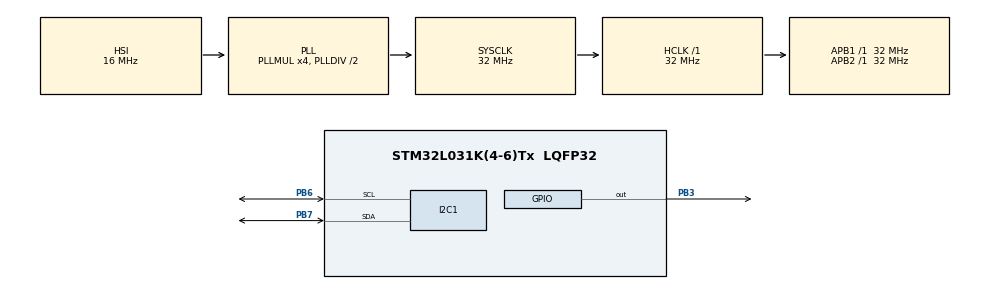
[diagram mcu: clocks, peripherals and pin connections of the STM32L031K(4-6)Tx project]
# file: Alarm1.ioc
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I2C1.Timing=0x00B07CB4
Mcu.Family=STM32L0
Mcu.Name=STM32L031K(4-6)Tx
Mcu.Package=LQFP32
NVIC.RTC_IRQn=true\:0\:0\:false\:false\:true\:true\:true\:true
PA13.Mode=Serial_Wire
PA13.Signal=SYS_SWDIO
PA14.Mode=Serial_Wire
PA14.Signal=SYS_SWCLK
PB3.Signal=GPIO_Output
PB6.GPIO_Pu=GPIO_NOPULL
PB6.Mode=I2C
PB6.Signal=I2C1_SCL
PB7.GPIO_Pu=GPIO_NOPULL
PB7.Mode=I2C
PB7.Signal=I2C1_SDA
PC14-OSC32_IN.Mode=LSE-External-Oscillator
PC14-OSC32_IN.Signal=RCC_OSC32_IN
PC15-OSC32_OUT.Mode=LSE-External-Oscillator
PC15-OSC32_OUT.Signal=RCC_OSC32_OUT
ProjectManager.HeapSize=0x200
ProjectManager.StackSize=0x400
ProjectManager.TargetToolchain=STM32CubeIDE
RCC.AHBFreq_Value=32000000
RCC.APB1Freq_Value=32000000
RCC.APB1TimFreq_Value=32000000
RCC.APB2Freq_Value=32000000
RCC.APB2TimFreq_Value=32000000
RCC.HCLKFreq_Value=32000000
RCC.HSE_VALUE=8000000
RCC.HSI16_VALUE=16000000
RCC.HSI48_VALUE=48000000
RCC.HSI_VALUE=16000000
RCC.MSI_VALUE=2097000
RCC.PLLMUL=RCC_PLLMUL_4
RCC.RTCClockSelection=RCC_RTCCLKSOURCE_LSE
RCC.RTCClockSelectionVirtual=RCC_RTCCLKSOURCE_LSE
RCC.SYSCLKFreq_VALUE=32000000
RCC.SYSCLKSource=RCC_SYSCLKSOURCE_PLLCLK
RCC.VCOOutputFreq_Value=64000000
RTC.Alarm-Alarm\ A=RTC_ALARM_A
RTC.Date=7
RTC.Format=RTC_FORMAT_BIN
RTC.Hours=12
RTC.Hours_A-Alarm\ A=12
RTC.Minutes=23
RTC.Minutes_A-Alarm\ A=32
RTC.Month=RTC_MONTH_JULY
RTC.Seconds_A-Alarm\ A=10
RTC.WeekDay=RTC_WEEKDAY_SUNDAY
VP_RTC_VS_RTC_Activate.Mode=RTC_Enabled
VP_RTC_VS_RTC_Alarm_A_Intern.Mode=Alarm A
VP_RTC_VS_RTC_Calendar.Mode=RTC_Calendar
board=NUCLEO-L031K6

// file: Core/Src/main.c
/* USER CODE BEGIN Header */
/**
  ******************************************************************************
  * @file           : main.c
  * @brief          : Main program body
  ******************************************************************************
  * @attention
  *
  * Copyright (c) 2026 STMicroelectronics.
  * All rights reserved.
  *
  * This software is licensed under terms that can be found in the LICENSE file
  * in the root directory of this software component.
  * If no LICENSE file comes with this software, it is provided AS-IS.
  *
  ******************************************************************************
  */
/* USER CODE END Header */
#include "main.h"
#include "PCA9548.h"

/* USER CODE BEGIN PM */

#define				BME280_ADDRESS				0xEC
#define				BME280_DEVICE_ID			0xD0
/* USER CODE END PM */

I2C_HandleTypeDef hi2c1;

RTC_HandleTypeDef hrtc;

/* USER CODE BEGIN PV */
uint8_t status,data,channel;
/* USER CODE END PV */

void SystemClock_Config(void);
static void MX_GPIO_Init(void);
static void MX_RTC_Init(void);
static void MX_I2C1_Init(void);

/* USER CODE BEGIN 0 */

/* Function to check whether the device is ready or not at corresponding address */
/*for (uint8_t addr = 0;  addr < 128; addr++)
{
	  if(HAL_I2C_IsDeviceReady(&hi2c1, addr << 1, 2, 100) == HAL_OK)
	  {
		  status = addr;
	  }
}*/

/* RTC Callback */
void HAL_RTC_AlarmAEventCallback(RTC_HandleTypeDef *hrtc)
{
	//
	HAL_GPIO_TogglePin(GPIOB, GPIO_PIN_3);
}

/* USER CODE END 0 */

int main(void)
{

  /* MCU Configuration--------------------------------------------------------*/

  /* Reset of all peripherals, Initializes the Flash interface and the Systick. */
  HAL_Init();

  /* Configure the system clock */
  SystemClock_Config();

  /* Initialize all configured peripherals */
  MX_GPIO_Init();
  MX_RTC_Init();
  MX_I2C1_Init();
  /* USER CODE BEGIN 2 */
  PCA9548_SelectChannel(PCA9548A_ADDR,PCA9548_CHANNEL0_ENABLED);

  status = HAL_I2C_Mem_Read(&hi2c1, BME280_ADDRESS, BME280_DEVICE_ID, 1, &data, 1, 100);

  //status = HAL_I2C_Master_Transmit(&hi2c1, PCA9548A_ADDR, &data, 1, HAL_MAX_DELAY);
  /* USER CODE END 2 */

  /* Infinite loop */
  while (1)
  {

  }
}

void SystemClock_Config(void)
{
  RCC_OscInitTypeDef RCC_OscInitStruct = {0};
  RCC_ClkInitTypeDef RCC_ClkInitStruct = {0};
  RCC_PeriphCLKInitTypeDef PeriphClkInit = {0};

  /** Configure the main internal regulator output voltage
  */
  __HAL_PWR_VOLTAGESCALING_CONFIG(PWR_REGULATOR_VOLTAGE_SCALE1);

  /** Configure LSE Drive Capability
  */
  HAL_PWR_EnableBkUpAccess();
  __HAL_RCC_LSEDRIVE_CONFIG(RCC_LSEDRIVE_LOW);

  /** Initializes the RCC Oscillators according to the specified parameters
  * in the RCC_OscInitTypeDef structure.
  */
  RCC_OscInitStruct.OscillatorType = RCC_OSCILLATORTYPE_HSI|RCC_OSCILLATORTYPE_LSE;
  RCC_OscInitStruct.LSEState = RCC_LSE_ON;
  RCC_OscInitStruct.HSIState = RCC_HSI_ON;
  RCC_OscInitStruct.HSICalibrationValue = RCC_HSICALIBRATION_DEFAULT;
  RCC_OscInitStruct.PLL.PLLState = RCC_PLL_ON;
  RCC_OscInitStruct.PLL.PLLSource = RCC_PLLSOURCE_HSI;
  RCC_OscInitStruct.PLL.PLLMUL = RCC_PLLMUL_4;
  RCC_OscInitStruct.PLL.PLLDIV = RCC_PLLDIV_2;
  if (HAL_RCC_OscConfig(&RCC_OscInitStruct) != HAL_OK)
  {
    Error_Handler();
  }

  /** Initializes the CPU, AHB and APB buses clocks
  */
  RCC_ClkInitStruct.ClockType = RCC_CLOCKTYPE_HCLK|RCC_CLOCKTYPE_SYSCLK
                              |RCC_CLOCKTYPE_PCLK1|RCC_CLOCKTYPE_PCLK2;
  RCC_ClkInitStruct.SYSCLKSource = RCC_SYSCLKSOURCE_PLLCLK;
  RCC_ClkInitStruct.AHBCLKDivider = RCC_SYSCLK_DIV1;
  RCC_ClkInitStruct.APB1CLKDivider = RCC_HCLK_DIV1;
  RCC_ClkInitStruct.APB2CLKDivider = RCC_HCLK_DIV1;

  if (HAL_RCC_ClockConfig(&RCC_ClkInitStruct, FLASH_LATENCY_1) != HAL_OK)
  {
    Error_Handler();
  }
  PeriphClkInit.PeriphClockSelection = RCC_PERIPHCLK_I2C1|RCC_PERIPHCLK_RTC;
  PeriphClkInit.I2c1ClockSelection = RCC_I2C1CLKSOURCE_PCLK1;
  PeriphClkInit.RTCClockSelection = RCC_RTCCLKSOURCE_LSE;
  if (HAL_RCCEx_PeriphCLKConfig(&PeriphClkInit) != HAL_OK)
  {
    Error_Handler();
  }
}

static void MX_I2C1_Init(void)
{

  hi2c1.Instance = I2C1;
  hi2c1.Init.Timing = 0x00B07CB4;
  hi2c1.Init.OwnAddress1 = 0;
  hi2c1.Init.AddressingMode = I2C_ADDRESSINGMODE_7BIT;
  hi2c1.Init.DualAddressMode = I2C_DUALADDRESS_DISABLE;
  hi2c1.Init.OwnAddress2 = 0;
  hi2c1.Init.OwnAddress2Masks = I2C_OA2_NOMASK;
  hi2c1.Init.GeneralCallMode = I2C_GENERALCALL_DISABLE;
  hi2c1.Init.NoStretchMode = I2C_NOSTRETCH_DISABLE;
  if (HAL_I2C_Init(&hi2c1) != HAL_OK)
  {
    Error_Handler();
  }

  /** Configure Analogue filter
  */
  if (HAL_I2CEx_ConfigAnalogFilter(&hi2c1, I2C_ANALOGFILTER_ENABLE) != HAL_OK)
  {
    Error_Handler();
  }

  /** Configure Digital filter
  */
  if (HAL_I2CEx_ConfigDigitalFilter(&hi2c1, 0) != HAL_OK)
  {
    Error_Handler();
  }

}

static void MX_RTC_Init(void)
{

  RTC_TimeTypeDef sTime = {0};
  RTC_DateTypeDef sDate = {0};
  RTC_AlarmTypeDef sAlarm = {0};

  /** Initialize RTC Only
  */
  hrtc.Instance = RTC;
  hrtc.Init.HourFormat = RTC_HOURFORMAT_24;
  hrtc.Init.AsynchPrediv = 127;
  hrtc.Init.SynchPrediv = 255;
  hrtc.Init.OutPut = RTC_OUTPUT_DISABLE;
  hrtc.Init.OutPutRemap = RTC_OUTPUT_REMAP_NONE;
  hrtc.Init.OutPutPolarity = RTC_OUTPUT_POLARITY_HIGH;
  hrtc.Init.OutPutType = RTC_OUTPUT_TYPE_OPENDRAIN;
  if (HAL_RTC_Init(&hrtc) != HAL_OK)
  {
    Error_Handler();
  }

  /** Initialize RTC and set the Time and Date
  */
  sTime.Hours = 12;
  sTime.Minutes = 23;
  sTime.Seconds = 0;
  sTime.DayLightSaving = RTC_DAYLIGHTSAVING_NONE;
  sTime.StoreOperation = RTC_STOREOPERATION_RESET;
  if (HAL_RTC_SetTime(&hrtc, &sTime, RTC_FORMAT_BIN) != HAL_OK)
  {
    Error_Handler();
  }
  sDate.WeekDay = RTC_WEEKDAY_SUNDAY;
  sDate.Month = RTC_MONTH_JULY;
  sDate.Date = 7;
  sDate.Year = 0;

  if (HAL_RTC_SetDate(&hrtc, &sDate, RTC_FORMAT_BIN) != HAL_OK)
  {
    Error_Handler();
  }

  /** Enable the Alarm A
  */
  sAlarm.AlarmTime.Hours = 12;
  sAlarm.AlarmTime.Minutes = 32;
  sAlarm.AlarmTime.Seconds = 10;
  sAlarm.AlarmTime.SubSeconds = 0;
  sAlarm.AlarmTime.DayLightSaving = RTC_DAYLIGHTSAVING_NONE;
  sAlarm.AlarmTime.StoreOperation = RTC_STOREOPERATION_RESET;
  sAlarm.AlarmMask = RTC_ALARMMASK_NONE;
  sAlarm.AlarmSubSecondMask = RTC_ALARMSUBSECONDMASK_ALL;
  sAlarm.AlarmDateWeekDaySel = RTC_ALARMDATEWEEKDAYSEL_DATE;
  sAlarm.AlarmDateWeekDay = 1;
  sAlarm.Alarm = RTC_ALARM_A;
  if (HAL_RTC_SetAlarm_IT(&hrtc, &sAlarm, RTC_FORMAT_BIN) != HAL_OK)
  {
    Error_Handler();
  }

}

static void MX_GPIO_Init(void)
{
  GPIO_InitTypeDef GPIO_InitStruct = {0};

  /* GPIO Ports Clock Enable */
  __HAL_RCC_GPIOC_CLK_ENABLE();
  __HAL_RCC_GPIOA_CLK_ENABLE();
  __HAL_RCC_GPIOB_CLK_ENABLE();

  /*Configure GPIO pin Output Level */
  HAL_GPIO_WritePin(GPIOB, GPIO_PIN_3, GPIO_PIN_RESET);

  /*Configure GPIO pin : PB3 */
  GPIO_InitStruct.Pin = GPIO_PIN_3;
  GPIO_InitStruct.Mode = GPIO_MODE_OUTPUT_PP;
  GPIO_InitStruct.Pull = GPIO_NOPULL;
  GPIO_InitStruct.Speed = GPIO_SPEED_FREQ_LOW;
  HAL_GPIO_Init(GPIOB, &GPIO_InitStruct);

}

void Error_Handler(void)
{
  __disable_irq();
  while (1)
  {
  }
}
